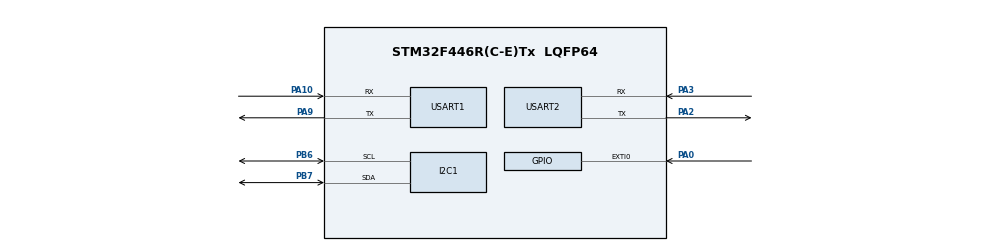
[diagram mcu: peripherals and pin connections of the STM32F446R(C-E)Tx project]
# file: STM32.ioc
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FREERTOS.Tasks01=defaultTask,24,128,StartDefaultTask,Default,NULL,Dynamic,NULL,NULL
FREERTOS.configUSE_NEWLIB_REENTRANT=1
Mcu.Family=STM32F4
Mcu.Name=STM32F446R(C-E)Tx
Mcu.Package=LQFP64
NVIC.EXTI0_IRQn=true\:0\:0\:false\:false\:true\:false\:true\:true\:true
NVIC.PriorityGroup=NVIC_PRIORITYGROUP_4
NVIC.TIM6_DAC_IRQn=true\:15\:0\:false\:false\:true\:false\:false\:true\:true
NVIC.TimeBase=TIM6_DAC_IRQn
NVIC.TimeBaseIP=TIM6
PA0-WKUP.Signal=GPXTI0
PA10.Mode=Asynchronous
PA10.Signal=USART1_RX
PA2.Mode=Asynchronous
PA2.Signal=USART2_TX
PA3.Mode=Asynchronous
PA3.Signal=USART2_RX
PA9.Mode=Asynchronous
PA9.Signal=USART1_TX
PB6.Mode=I2C
PB6.Signal=I2C1_SCL
PB7.Mode=I2C
PB7.Signal=I2C1_SDA
ProjectManager.HeapSize=0x200
ProjectManager.StackSize=0x400
ProjectManager.TargetToolchain=STM32CubeIDE
RCC.APB1Freq_Value=16000000
RCC.APB1TimFreq_Value=16000000
RCC.APB2Freq_Value=16000000
RCC.APB2TimFreq_Value=16000000
RCC.CortexFreq_Value=16000000
RCC.USBFreq_Value=96000000
RCC.VCOOutputFreq_Value=192000000
USART1.VirtualMode=VM_ASYNC
USART2.VirtualMode=VM_ASYNC
VP_FREERTOS_VS_CMSIS_V2.Mode=CMSIS_V2
VP_SYS_VS_tim6.Mode=TIM6
board=custom

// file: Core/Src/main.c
/* USER CODE BEGIN Header */
/**
  ******************************************************************************
  * @file           : main.c
  * @brief          : Main program body
  ******************************************************************************
  * @attention
  *
  * Copyright (c) 2026 STMicroelectronics.
  * All rights reserved.
  *
  * This software is licensed under terms that can be found in the LICENSE file
  * in the root directory of this software component.
  * If no LICENSE file comes with this software, it is provided AS-IS.
  *
  ******************************************************************************
  */
/* USER CODE END Header */
#include "main.h"
#include "cmsis_os.h"

/* USER CODE BEGIN Includes */
#include "adxl345.h"
#include "seismo.h"
/* USER CODE END Includes */

I2C_HandleTypeDef hi2c1;

UART_HandleTypeDef huart1;
UART_HandleTypeDef huart2;

/* Definitions for defaultTask */
osThreadId_t defaultTaskHandle;
const osThreadAttr_t defaultTask_attributes = {
  .name = "defaultTask",
  .stack_size = 128 * 4,
  .priority = (osPriority_t) osPriorityNormal,
};

void SystemClock_Config(void);
static void MX_GPIO_Init(void);
static void MX_I2C1_Init(void);
static void MX_USART2_UART_Init(void);
static void MX_USART1_UART_Init(void);
void StartDefaultTask(void *argument);

int main(void)
{

  /* MCU Configuration--------------------------------------------------------*/

  /* Reset of all peripherals, Initializes the Flash interface and the Systick. */
  HAL_Init();

  /* Configure the system clock */
  SystemClock_Config();

  /* Initialize all configured peripherals */
  MX_GPIO_Init();
  MX_I2C1_Init();
  MX_USART2_UART_Init();
  MX_USART1_UART_Init();
  /* USER CODE BEGIN 2 */

//  if (ADXL345_Init() != HAL_OK)
//  {
//      const char msg[] =
//          "ADXL345 init failed! Check wiring/ID.\r\n";
//
//      /* USART1 is reserved for binary packets to the ESP32. */
//      HAL_UART_Transmit(
//          &huart1,
//          (uint8_t *)msg,
//          sizeof(msg) - 1,
//          100);
//
//      Error_Handler();

  /* Continue temporarily for UART diagnostics. */
//  }
  /* USER CODE END 2 */

  /* Init scheduler */
  osKernelInitialize();
  HAL_StatusTypeDef adxlStatus = ADXL345_Init();
   if (adxlStatus == HAL_OK)
   {
       const char msg[] = "ADXL345 INITIALIZED OK\r\n";
       HAL_UART_Transmit(&huart2,
                         (uint8_t *)msg,
                         sizeof(msg) - 1,
                         100);
   }
   else
   {
       const char msg[] = "ADXL345 INITIALIZATION FAILED!\r\n";
       HAL_UART_Transmit(&huart2,
                         (uint8_t *)msg,
                         sizeof(msg) - 1,
                         100);
   }

  /* Create the thread(s) */
  /* creation of defaultTask */
  defaultTaskHandle = osThreadNew(StartDefaultTask, NULL, &defaultTask_attributes);

  /* USER CODE BEGIN RTOS_THREADS */
  if (Seismo_Init() != HAL_OK)
  {
      Error_Handler();
  }
  /* USER CODE END RTOS_THREADS */

  /* Start scheduler */
  osKernelStart();

  /* We should never get here as control is now taken by the scheduler */

  /* Infinite loop */
  while (1)
  {

  }
}

void SystemClock_Config(void)
{
  RCC_OscInitTypeDef RCC_OscInitStruct = {0};
  RCC_ClkInitTypeDef RCC_ClkInitStruct = {0};

  /** Configure the main internal regulator output voltage
  */
  __HAL_RCC_PWR_CLK_ENABLE();
  __HAL_PWR_VOLTAGESCALING_CONFIG(PWR_REGULATOR_VOLTAGE_SCALE3);

  /** Initializes the RCC Oscillators according to the specified parameters
  * in the RCC_OscInitTypeDef structure.
  */
  RCC_OscInitStruct.OscillatorType = RCC_OSCILLATORTYPE_HSI;
  RCC_OscInitStruct.HSIState = RCC_HSI_ON;
  RCC_OscInitStruct.HSICalibrationValue = RCC_HSICALIBRATION_DEFAULT;
  RCC_OscInitStruct.PLL.PLLState = RCC_PLL_NONE;
  if (HAL_RCC_OscConfig(&RCC_OscInitStruct) != HAL_OK)
  {
    Error_Handler();
  }

  /** Initializes the CPU, AHB and APB buses clocks
  */
  RCC_ClkInitStruct.ClockType = RCC_CLOCKTYPE_HCLK|RCC_CLOCKTYPE_SYSCLK
                              |RCC_CLOCKTYPE_PCLK1|RCC_CLOCKTYPE_PCLK2;
  RCC_ClkInitStruct.SYSCLKSource = RCC_SYSCLKSOURCE_HSI;
  RCC_ClkInitStruct.AHBCLKDivider = RCC_SYSCLK_DIV1;
  RCC_ClkInitStruct.APB1CLKDivider = RCC_HCLK_DIV1;
  RCC_ClkInitStruct.APB2CLKDivider = RCC_HCLK_DIV1;

  if (HAL_RCC_ClockConfig(&RCC_ClkInitStruct, FLASH_LATENCY_0) != HAL_OK)
  {
    Error_Handler();
  }
}

static void MX_I2C1_Init(void)
{

  hi2c1.Instance = I2C1;
  hi2c1.Init.ClockSpeed = 100000;
  hi2c1.Init.DutyCycle = I2C_DUTYCYCLE_2;
  hi2c1.Init.OwnAddress1 = 0;
  hi2c1.Init.AddressingMode = I2C_ADDRESSINGMODE_7BIT;
  hi2c1.Init.DualAddressMode = I2C_DUALADDRESS_DISABLE;
  hi2c1.Init.OwnAddress2 = 0;
  hi2c1.Init.GeneralCallMode = I2C_GENERALCALL_DISABLE;
  hi2c1.Init.NoStretchMode = I2C_NOSTRETCH_DISABLE;
  if (HAL_I2C_Init(&hi2c1) != HAL_OK)
  {
    Error_Handler();
  }

}

static void MX_USART1_UART_Init(void)
{

  huart1.Instance = USART1;
  huart1.Init.BaudRate = 115200;
  huart1.Init.WordLength = UART_WORDLENGTH_8B;
  huart1.Init.StopBits = UART_STOPBITS_1;
  huart1.Init.Parity = UART_PARITY_NONE;
  huart1.Init.Mode = UART_MODE_TX_RX;
  huart1.Init.HwFlowCtl = UART_HWCONTROL_NONE;
  huart1.Init.OverSampling = UART_OVERSAMPLING_16;
  if (HAL_UART_Init(&huart1) != HAL_OK)
  {
    Error_Handler();
  }

}

static void MX_USART2_UART_Init(void)
{

  huart2.Instance = USART2;
  huart2.Init.BaudRate = 115200;
  huart2.Init.WordLength = UART_WORDLENGTH_8B;
  huart2.Init.StopBits = UART_STOPBITS_1;
  huart2.Init.Parity = UART_PARITY_NONE;
  huart2.Init.Mode = UART_MODE_TX_RX;
  huart2.Init.HwFlowCtl = UART_HWCONTROL_NONE;
  huart2.Init.OverSampling = UART_OVERSAMPLING_16;
  if (HAL_UART_Init(&huart2) != HAL_OK)
  {
    Error_Handler();
  }

}

static void MX_GPIO_Init(void)
{
  GPIO_InitTypeDef GPIO_InitStruct = {0};

  /* GPIO Ports Clock Enable */
  __HAL_RCC_GPIOA_CLK_ENABLE();
  __HAL_RCC_GPIOB_CLK_ENABLE();

  /*Configure GPIO pin : PA0 */
  GPIO_InitStruct.Pin = GPIO_PIN_0;
  GPIO_InitStruct.Mode = GPIO_MODE_IT_RISING;
  GPIO_InitStruct.Pull = GPIO_NOPULL;
  HAL_GPIO_Init(GPIOA, &GPIO_InitStruct);

  /* EXTI interrupt init*/
  HAL_NVIC_SetPriority(EXTI0_IRQn, 5, 0);
  HAL_NVIC_EnableIRQ(EXTI0_IRQn);

}

/* USER CODE BEGIN 4 */
void HAL_GPIO_EXTI_Callback(uint16_t GPIO_Pin)
{
    if (GPIO_Pin == GPIO_PIN_0)
    {
        Seismo_DataReadyISR();
    }
}
/* USER CODE END 4 */

void StartDefaultTask(void *argument)
{
  for(;;)
  {
    osDelay(1);
  }
}

void HAL_TIM_PeriodElapsedCallback(TIM_HandleTypeDef *htim)
{
  if (htim->Instance == TIM6)
  {
    HAL_IncTick();
  }
}

void Error_Handler(void)
{
  __disable_irq();
  while (1)
  {
  }
}
